# CY8C4xxx register map
File version: 0.1
Registers are 8-bit, read-write, no defined reset value unless marked. A register's access mark holds for its fields unless they carry their own. Offsets are from the block's base; [hi:lo] are bit positions; {n}, {i} and the like mark numbered series; 'fields as' and 'values as' point back to an identical list.

## UDB_PA0 — Port Adapter Configuration
Base 0x400F5000; alternate view of UDB
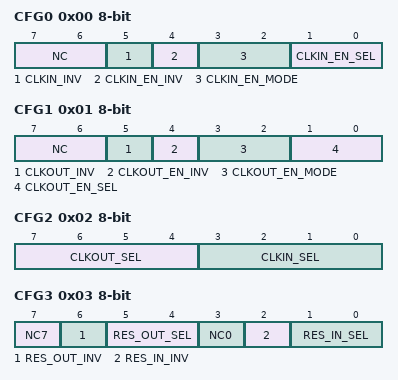
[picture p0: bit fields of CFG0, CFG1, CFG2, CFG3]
0x00 CFG0 — PA Data In Clock Control Register
  [7:6] NC — Spare register bits
  [5] CLKIN_INV — Determines whether the selected clock is inverted or not.
    0=NOINV; 1=INV
  [4] CLKIN_EN_INV — Determines whether the selected enable is inverted or not.
    0=NOINV; 1=INV
  [3:2] CLKIN_EN_MODE — Select one of four operating modes
    0=OFF; 1=ON; 2=POSEDGE; 3=LEVEL
  [1:0] CLKIN_EN_SEL — Select one of four choices for clock enable
    0=PIN_RC; 1=DSI_RC_0; 2=DSI_RC_1; 3=DSI_RC_2
0x01 CFG1 — PA Data Out Clock Control Register
  [7:6] NC — Spare register bits
  [5] CLKOUT_INV — Determines whether the selected clock is inverted or not.
    0=NOINV; 1=INV
  [4] CLKOUT_EN_INV — Determines whether the selected enable is inverted or not.
    0=NOINV; 1=INV
  [3:2] CLKOUT_EN_MODE — Select one of four operating modes
    0=OFF; 1=ON; 2=POSEDGE; 3=LEVEL
  [1:0] CLKOUT_EN_SEL — Select one of four choices for clock enable
    0=PIN_RC; 1=DSI_RC_0; 2=DSI_RC_1; 3=DSI_RC_2
0x02 CFG2 — PA Clock Select Register
  [7:4] CLKOUT_SEL — Select one of four choices for clock enable
    {v}=GCLK{v} (v=0..7); 9=BUS_CLK_APP; 12=PIN_RC; 13=DSI_RC_0; 14=DSI_RC_1; 15=DSI_RC_2
  [3:0] CLKIN_SEL — Select one of four choices for clock enable
    values as CLKOUT_SEL
0x03 CFG3 — PA Reset Select Register
  [7] NC7 — Spare register bit
  [6] RES_OUT_INV — Select the polarity of the reset control.
    0=NOINV; 1=INV
  [5:4] RES_OUT_SEL — Select one of four inputs to serve as the reset control to the block.
    0=PIN_RC; 1=DSI_RC_0; 2=DSI_RC_1; 3=DSI_RC_2
  [3] NC0 — Spare register bit
  [2] RES_IN_INV — Select the polarity of the reset control.
    0=NOINV; 1=INV
  [1:0] RES_IN_SEL — Select one of four inputs to serve as the reset control to the block.
    0=PIN_RC; 1=DSI_RC_0; 2=DSI_RC_1; 3=DSI_RC_2
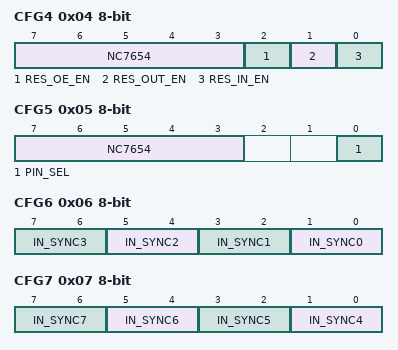
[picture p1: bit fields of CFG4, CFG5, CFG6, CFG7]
0x04 CFG4 — PA Reset Enable Register
  [7:3] NC7654 — Spare register bits
  [2] RES_OE_EN — Enable the selected reset
    0=DISABLE; 1=ENABLE
  [1] RES_OUT_EN — Enable the selected reset
    0=DISABLE; 1=ENABLE
  [0] RES_IN_EN — Enable the selected reset
    0=DISABLE; 1=ENABLE
0x05 CFG5 — PA Reset Pin Select Register
  [7:3] NC7654 — Spare register bits
  [0] PIN_SEL — Select port input to route to reset multiplexer (dsi_xx_input_p[7:0])
    {v}=PIN{v} (v=0..7)
0x06 CFG6 — PA Input Data Sync Control Register - Low
  [all] fields
    0=TRANSPARENT; 1=SINGLESYNC; 2=DOUBLESYNC
  [2n+1:2n] IN_SYNC{n} (n=0..3) — Synchronization selection for PA input {n}
0x07 CFG7 — PA Input Data Sync Control Register - High
  [all] fields
    0=TRANSPARENT; 1=SINGLESYNC; 2=DOUBLESYNC
  [2n-7:2n-8] IN_SYNC{n} (n=4..7) — Synchronization selection for PA input {n}
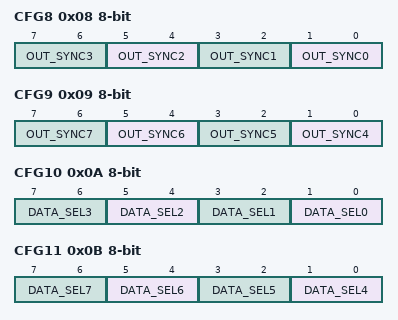
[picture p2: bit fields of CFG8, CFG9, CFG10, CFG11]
0x08 CFG8 — PA Output Data Sync Control Register - Low
  [all] fields
    0=TRANSPARENT; 1=SINGLESYNC; 2=CLOCK; 3=CLOCKINV
  [2n+1:2n] OUT_SYNC{n} (n=0..3) — Synchronization selection for PA output {n}
0x09 CFG9 — PA Output Data Sync Control Register - High
  [all] fields
    0=TRANSPARENT; 1=SINGLESYNC; 2=CLOCK; 3=CLOCKINV
  [2n-7:2n-8] OUT_SYNC{n} (n=4..7) — Synchronization selection for PA output {n}
0x0A CFG10 — PA Output Data Select Register - Low
  [all] fields
    {v}=DSI_OUTPUT{v} (v=0..3)
  [2n+1:2n] DATA_SEL{n} (n=0..3) — Data selection for PA output {n}
0x0B CFG11 — PA Output Data Select Register - High
  [all] fields
    {v}=DSI_OUTPUT{v} (v=0..3)
  [2n-7:2n-8] DATA_SEL{n} (n=4..7) — Data selection for PA output {n}
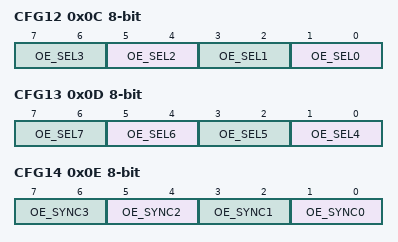
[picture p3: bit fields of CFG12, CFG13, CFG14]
0x0C CFG12 — PA OE Select Register - Low
  [all] fields
    {v}=DSI_OE_OUT{v} (v=0..3)
  [2n+1:2n] OE_SEL{n} (n=0..3) — Data selection for PA oe {n}
0x0D CFG13 — PA OE Select Register - High
  [all] fields
    {v}=DSI_OE_OUT{v} (v=0..3)
  [2n-7:2n-8] OE_SEL{n} (n=4..7) — Data selection for PA oe {n}
0x0E CFG14 — PA OE Sync Register
  [all] fields
    0=TRANSPARENT; 1=SINGLESYNC; 2=CONSTANT1; 3=CONSTANT0
  [2n+1:2n] OE_SYNC{n} (n=0..3) — Synchronization options for dsi_to_oe[{n}]

## UDB_PA1 — Port Adapter Configuration
Base 0x400F5010; alternate view of UDB
Registers as UDB_PA0.

## UDB_PA2 — Port Adapter Configuration
Base 0x400F5020; alternate view of UDB
Registers as UDB_PA0.

## UDB_PA3 — Port Adapter Configuration
Base 0x400F5030; alternate view of UDB
Registers as UDB_PA0.
